# RZT2H register map
Vendor: Renesas Electronics Corporation; Series: RZT; File version: 1.00.00
CPU: other r0p0, little endian, MPU, no FPU, VTOR, 4 interrupt priority bits, 624 interrupts
Registers are 32-bit, read-write, reset 0x0 unless marked. A register's access mark holds for its fields unless they carry their own. Offsets are from the block's base; [hi:lo] are bit positions; {n}, {i} and the like mark numbered series.

## ETHSW_PTP — Ethernet Switch for PTP
Base 0x80110400
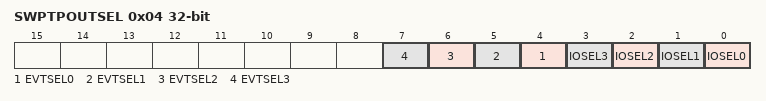
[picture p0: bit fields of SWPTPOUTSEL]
0x04 SWPTPOUTSEL — ETHSW_PTPOUT Select Register
  [n+4] EVTSEL{n} (n=0..3) — Select the source of the ETHSW_PTPOUT{n} event for GIC, DMAC, and ELC
    0=Pulse generator {n} output; 1=TDMA_GPIO[{n+4}] output
  [n] IOSEL{n} (n=0..3) — Select the source of the ETHSW_PTPOUT{n} output signal
    0=Pulse generator {n} output; 1=TDMA_GPIO[{n+4}] output
{0x400+0x100*i} SWTMEN{i} (i=0..3) — PTP Timer Pulse Output Enable {i} Register
  [0] OUTEN — Enable ETHSW_PTPOUTn Signal Output
    0=Disabled; 1=Enabled
{0x404+0x100*i} SWTMSTSEC{i} (i=0..3) — PTP Timer Pulse Start Second {i} Register
  [31:0] STSEC
{0x408+0x100*i} SWTMSTNS{i} (i=0..3) — PTP Timer Pulse Start Nanosecond {i} Register
  [31:0] STNS — Start Time by Nanosecond
{0x40C+0x100*i} SWTMPSEC{i} (i=0..3) — PTP Timer Pulse Period Second {i} Register
  [31:0] PSEC
{0x410+0x100*i} SWTMPNS{i} (i=0..3) reset 0x3B9ACA00 — PTP Timer Pulse Period Nanosecond {i} Register
  [31:0] PNS — Period by Nanosecond
{0x414+0x100*i} SWTMWTH{i} (i=0..3) reset 0x3 — PTP Timer Pulse Width {i} Register
  [15:0] WIDTH — Set the Pulse Width of ETHSW_PTPOUTn in the cycle number of ts_clk (8 ns).
{0x418+0x100*i} SWTMMAXP{i} (i=0..3) reset 0x3B9ACA00 — PTP Timer Pulse Max Nanosecond {i} Register
  [31:0] MAXP — Sets the boundary value in nanoseconds to carry from the nanosecond field to the second field. The same value as ATIME_EVT_PERIOD register must be set.
{0x41C+0x100*i} SWTMLATSEC{i} (i=0..3) — PTP Timer Pulse Latch Second {i} Register
  [31:0] LATSEC
{0x420+0x100*i} SWTMLATNS{i} (i=0..3) — PTP Timer Pulse Latch Nanosecond {i} Register
  [31:0] LATNS

## GMACC
Base 0x80110400
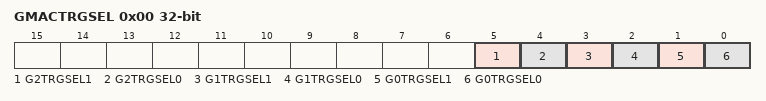
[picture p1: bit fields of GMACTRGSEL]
0x00 GMACTRGSEL
  [5] G2TRGSEL1, [4] G2TRGSEL0, [3] G1TRGSEL1, [2] G1TRGSEL0, [1] G0TRGSEL1, [0] G0TRGSEL0

## SHOSTIF
Base 0x80241000
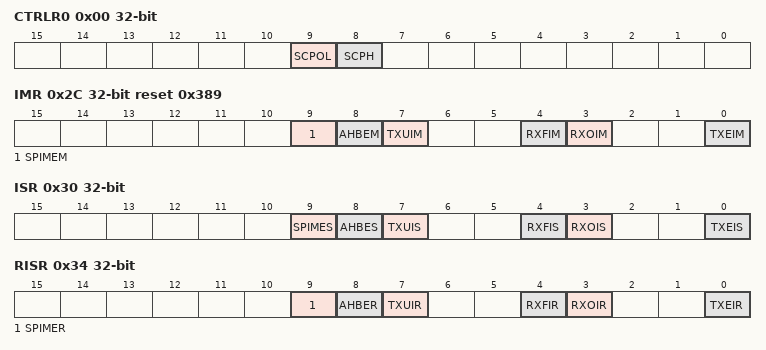
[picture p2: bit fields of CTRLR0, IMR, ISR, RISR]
0x00 CTRLR0
  [9] SCPOL, [8] SCPH
0x08 ENR
  [0] ENABLE
0x14 RXFBTR reset 0x3F
  [5:0] RXFBTL
0x18 TXFTLR
  [5:0] TFT
0x1C RXFTLR
  [5:0] RFT
0x28 SR ro
  [0] BUSY
0x2C IMR reset 0x389
  [9] SPIMEM, [8] AHBEM, [7] TXUIM, [4] RXFIM, [3] RXOIM, [0] TXEIM
0x30 ISR ro (reset mask 0xFFFFFFFE)
  [9] SPIMES, [8] AHBES, [7] TXUIS, [4] RXFIS, [3] RXOIS, [0] TXEIS
0x34 RISR ro (reset mask 0xFFFFFFFE)
  [9] SPIMER, [8] AHBER, [7] TXUIR, [4] RXFIR, [3] RXOIR, [0] TXEIR
0x38 TXUICR ro
  [0] TXUICR
0x3C RXOICR ro
  [0] RXOICR
0x40 SPIMECR ro
  [0] SPIMECR
0x44 AHBECR ro
  [0] AHBECR
0x48 ICR ro
  [0] ICR

## ELO — Event Link Option Setting
Base 0x80290000
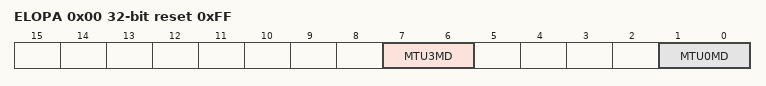
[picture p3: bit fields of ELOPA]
0x00 ELOPA reset 0xFF — Event Link Option Setting Register A
  [7:6] MTU3MD — MTU3 Operation Select
    0=Counting is started; 1=Counting is restarted; 2=Input capture (The MTU3.TCNT value is captured into MTU3.TGRA.); 3=Event is disabled
  [1:0] MTU0MD — MTU0 Operation Select
    0=Counting is started; 1=Counting is restarted; 2=Input capture (The MTU0.TCNT value is captured into MTU0.TGRA.); 3=Event is disabled
0x04 ELOPB reset 0xFF — Event Link Option Setting Register B
  [1:0] MTU4MD — MTU4 Operation Select
    0=Counting is started; 1=Counting is restarted; 2=Input capture (The MTU4.TCNT value is captured into MTU4.TGRA.); 3=Event is disabled

## GPT_IC — Input Capture Selection
Base 0x80290008
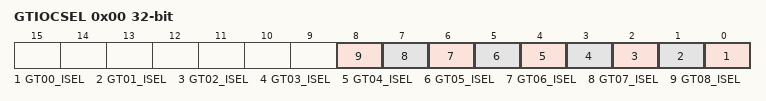
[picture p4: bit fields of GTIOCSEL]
0x00 GTIOCSEL (alternate view of ELOPA) — General PWM Timer Input Capture Signal Select Register
  [n] GT{n:02}_ISEL (n=0..8)
    0=GTIOC{n:02}_4A / GTIOC{n:02}_4B input signals are selected; 1=GTIOC{n:02}_3A / GTIOC{n:02}_3B input signals are selected

## PCIE_SPL0 — PCIe Supplemental Settings Channel 0
Base 0x80292000
Same registers: PCIE_SPL1 0x80292030
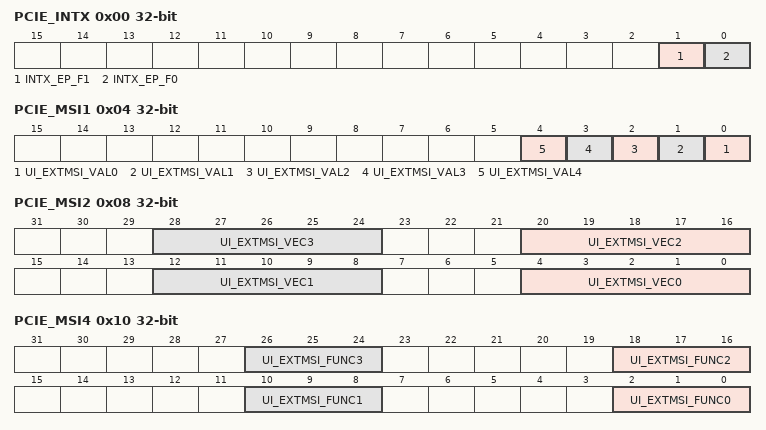
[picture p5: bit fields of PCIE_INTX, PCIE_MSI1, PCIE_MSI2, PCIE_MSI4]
0x00 PCIE_INTX
  [1] INTX_EP_F1 — Legacy Interrupt (Assert_INTx/Deassert_INTx message) Trigger for Endpoint Funtion #1
    0=Issue Deassert_INTx message; 1=Issue Assert_INTx message
  [0] INTX_EP_F0 — Legacy Interrupt (Assert_INTx/Deassert_INTx message) Trigger for Endpoint Funtion #0
    0=Issue Deassert_INTx message; 1=Issue Assert_INTx message
0x04 PCIE_MSI1 wo — PCIe MSI Register 1
  [n] UI_EXTMSI_VAL{n} (n=0..4) — MSI {n} Interrupt Trigger for Endpoint
0x08 PCIE_MSI2 — PCIe MSI Register 2
  [8n+4:8n] UI_EXTMSI_VEC{n} (n=0..3) — Specify the interrupt vector of MSI {n} interrupt for Endpoint.
0x0C PCIE_MSI3 — PCIe MSI Register 3
  [4:0] UI_EXTMSI_VEC4 — Specify the interrupt vector of MSI 4 interrupt for Endpoint.
0x10 PCIE_MSI4 — PCIe MSI Register 4
  [8n+2:8n] UI_EXTMSI_FUNC{n} (n=0..3) — Specify the interrupt function number of MSI {n} interrupt for Endpoint.
0x14 PCIE_MSI5 — PCIe MSI Register 5
  [2:0] UI_EXTMSI_FUNC4 — Specify the interrupt function number of MSI 4 interrupt for Endpoint.
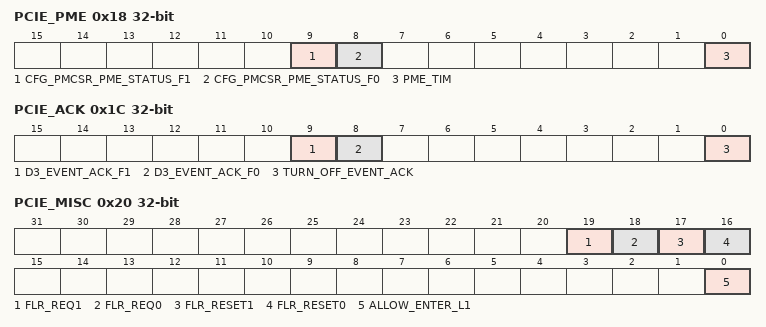
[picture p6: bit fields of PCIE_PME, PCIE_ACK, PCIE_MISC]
0x18 PCIE_PME
  [9] CFG_PMCSR_PME_STATUS_F1 — Power Management Event Setting for Endpoint Function #1
  [8] CFG_PMCSR_PME_STATUS_F0 — Power Management Event Setting for Endpoint Function #0
  [0] PME_TIM — PM_PME Message Clock for Endpoint
0x1C PCIE_ACK wo
  [9] D3_EVENT_ACK_F1 — Acknowledge to Power State Transition for Endpoint Function #1
  [8] D3_EVENT_ACK_F0 — Acknowledge to Power State Transition for Endpoint Function #0
  [0] TURN_OFF_EVENT_ACK — Acknowledge to PME_Turn_Off Message for Endpoint
0x20 PCIE_MISC
  [19] FLR_REQ1 ro — Indicates FLR Request for Funtion #1
  [18] FLR_REQ0 ro — Indicates FLR Request for Funtion #0
  [17] FLR_RESET1 wo — Function Level Reset (FLR) for Function #1
  [16] FLR_RESET0 wo — Function Level Reset (FLR) for Function #0
  [0] ALLOW_ENTER_L1 — ASPM L1 State Transition Permission
    0=Not permitted to transit from ASPM L0 to ASPM L1 state; 1=Permitted to transit from ASPM L0 to ASPM L1 state
0x24 PCIE_MODE
  [0] MODE_PORT — Device Type Select
    0=Endpoint; 1=Root Complex
